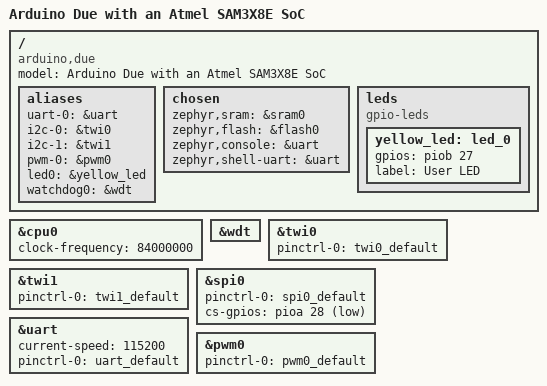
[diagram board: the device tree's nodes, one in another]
/* SPDX-License-Identifier: Apache-2.0 */

/dts-v1/;

#include <atmel/sam3x.dtsi>
#include "arduino_due-pinctrl.dtsi"
#include "arduino_r3_connector.dtsi"

/ {
	compatible = "arduino,due", "atmel,sam3x8e", "atmel,sam3x";
	model = "Arduino Due with an Atmel SAM3X8E SoC";

	aliases {
		uart-0 = &uart;
		i2c-0 = &twi0;
		i2c-1 = &twi1;
		pwm-0 = &pwm0;
		led0 = &yellow_led;
		watchdog0 = &wdt;
	};

	chosen {
		zephyr,sram = &sram0;
		zephyr,flash = &flash0;
		zephyr,console = &uart;
		zephyr,shell-uart = &uart;
	};

	leds {
		compatible = "gpio-leds";

		yellow_led: led_0 {
			gpios = <&piob 27 0>;
			label = "User LED";
		};
	};
};

&cpu0 {
	clock-frequency = <84000000>;
};

&wdt {
	status = "okay";
};

&twi0 {
	pinctrl-0 = <&twi0_default>;
	pinctrl-names = "default";
	status = "okay";
};

&twi1 {
	pinctrl-0 = <&twi1_default>;
	pinctrl-names = "default";
	status = "okay";
};

&spi0 {
	pinctrl-0 = <&spi0_default>;
	pinctrl-names = "default";
	cs-gpios = <&pioa 28 GPIO_ACTIVE_LOW>;
	status = "okay";
};

&uart {
	current-speed = <115200>;

	pinctrl-0 = <&uart_default>;
	pinctrl-names = "default";
	status = "okay";
};

&pwm0 {
	pinctrl-0 = <&pwm0_default>;
	pinctrl-names = "default";
	status = "okay";
};

arduino_i2c: &twi1 {};
